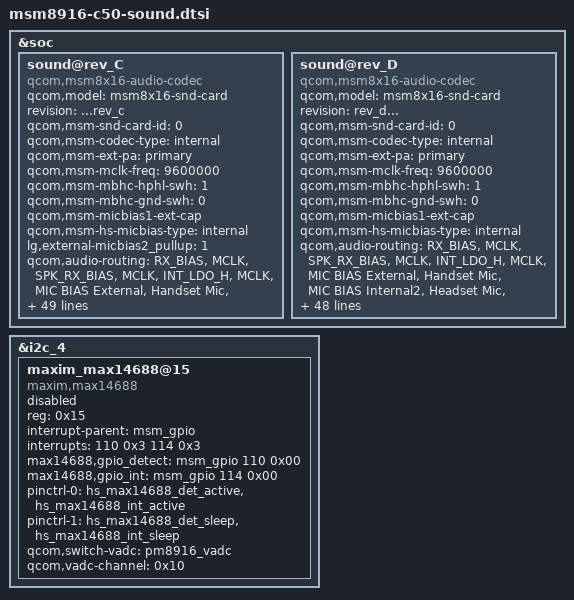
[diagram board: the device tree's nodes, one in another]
/* Copyright (c) 2012, Code Aurora Forum. All rights reserved.
 *
 * This program is free software; you can redistribute it and/or modify
 * it under the terms of the GNU General Public License version 2 and
 * only version 2 as published by the Free Software Foundation.
 *
 * This program is distributed in the hope that it will be useful,
 * but WITHOUT ANY WARRANTY; without even the implied warranty of
 * MERCHANTABILITY or FITNESS FOR A PARTICULAR PURPOSE.  See the
 * GNU General Public License for more details.
 */

&soc {
	sound@rev_C {
		compatible = "qcom,msm8x16-audio-codec";
		qcom,model = "msm8x16-snd-card";
		revision = "...rev_c";
		qcom,msm-snd-card-id = <0>;
		qcom,msm-codec-type = "internal";
		qcom,msm-ext-pa = "primary";
		qcom,msm-mclk-freq = <9600000>;
		qcom,msm-mbhc-hphl-swh = <1>;	/*LGE AUDIO BSP MODIFIED 0 to 1*/
		qcom,msm-mbhc-gnd-swh = <0>;
		qcom,msm-micbias1-ext-cap;
		qcom,msm-hs-micbias-type = "internal";
		lg,external-micbias2_pullup = <1>;
		qcom,audio-routing =
			"RX_BIAS", "MCLK",
			"SPK_RX_BIAS", "MCLK",
			"INT_LDO_H", "MCLK",
			"MIC BIAS External", "Handset Mic",
			"MIC BIAS Internal2", "Headset Mic",
			"MIC BIAS External", "Secondary Mic",
			"AMIC1", "MIC BIAS External",
			"AMIC2", "MIC BIAS Internal2",
			"AMIC3", "MIC BIAS External",
			"DMIC1", "MIC BIAS Internal1",
			"MIC BIAS Internal1", "Digital Mic1",
			"DMIC2", "MIC BIAS Internal1",
			"MIC BIAS Internal1", "Digital Mic2";
		pinctrl-names = "cdc_lines_act",
				"cdc_lines_sus",
				"cdc_lines_sec_ext_act",
				"cdc_lines_sec_ext_sus",
				"cross_conn_det_act",
				"cross_conn_det_sus";
		pinctrl-0 = <&cdc_pdm_lines_act>;
		pinctrl-1 = <&cdc_pdm_lines_sus>;
		pinctrl-2 = <&cdc_pdm_lines_act &cdc_ext_pa_act
						&cdc_ext_pa_ws_act>;
		pinctrl-3 = <&cdc_pdm_lines_sus &cdc_ext_pa_sus
						&cdc_ext_pa_ws_sus>;
		pinctrl-4 = <&cross_conn_det_act>;
		pinctrl-5 = <&cross_conn_det_sus>;
		//qcom,cdc-us-euro-gpios = <&msm_gpio 120 0>; /*LGE AUDIO BSP MODIFIED do not use*/
		asoc-platform = <&pcm0>, <&pcm1>, <&voip>, <&voice>,
				<&loopback>, <&compress>, <&hostless>,
				<&afe>, <&lsm>, <&routing>, <&lpa>;
		asoc-platform-names = "msm-pcm-dsp.0", "msm-pcm-dsp.1",
				"msm-voip-dsp", "msm-pcm-voice", "msm-pcm-loopback",
				"msm-compress-dsp", "msm-pcm-hostless", "msm-pcm-afe",
				"msm-lsm-client", "msm-pcm-routing", "msm-pcm-lpa";
		asoc-cpu = <&dai_pri_auxpcm>, <&dai_hdmi>,
				<&dai_mi2s0>, <&dai_mi2s1>, <&dai_mi2s2>, <&dai_mi2s3>,
				<&sb_0_rx>, <&sb_0_tx>, <&sb_1_rx>, <&sb_1_tx>,
				<&sb_3_rx>, <&sb_3_tx>, <&sb_4_rx>, <&sb_4_tx>,
				<&bt_sco_rx>, <&bt_sco_tx>, <&int_fm_rx>, <&int_fm_tx>,
				<&afe_pcm_rx>, <&afe_pcm_tx>, <&afe_proxy_rx>, <&afe_proxy_tx>,
				<&incall_record_rx>, <&incall_record_tx>, <&incall_music_rx>,
				<&incall_music_2_rx>;
		asoc-cpu-names = "msm-dai-q6-auxpcm.1", "msm-dai-q6-hdmi.8",
				"msm-dai-q6-mi2s.0", "msm-dai-q6-mi2s.1",
				"msm-dai-q6-mi2s.2", "msm-dai-q6-mi2s.3",
				"msm-dai-q6-dev.16384", "msm-dai-q6-dev.16385",
				"msm-dai-q6-dev.16386", "msm-dai-q6-dev.16387",
				"msm-dai-q6-dev.16390", "msm-dai-q6-dev.16391",
				"msm-dai-q6-dev.16392", "msm-dai-q6-dev.16393",
				"msm-dai-q6-dev.12288", "msm-dai-q6-dev.12289",
				"msm-dai-q6-dev.12292", "msm-dai-q6-dev.12293",
				"msm-dai-q6-dev.224", "msm-dai-q6-dev.225",
				"msm-dai-q6-dev.241", "msm-dai-q6-dev.240",
				"msm-dai-q6-dev.32771", "msm-dai-q6-dev.32772",
				"msm-dai-q6-dev.32773", "msm-dai-q6-dev.32770";
		asoc-codec = <&stub_codec>, <&pm8916_tombak_dig>;
		asoc-codec-names = "msm-stub-codec.1", "tombak_codec";
	};
	sound@rev_D {
		compatible = "qcom,msm8x16-audio-codec";
		qcom,model = "msm8x16-snd-card";
		revision = "rev_d...";
		qcom,msm-snd-card-id = <0>;
		qcom,msm-codec-type = "internal";
		qcom,msm-ext-pa = "primary";
		qcom,msm-mclk-freq = <9600000>;
		qcom,msm-mbhc-hphl-swh = <1>;	/*LGE AUDIO BSP MODIFIED 0 to 1*/
		qcom,msm-mbhc-gnd-swh = <0>;
		qcom,msm-micbias1-ext-cap;
		qcom,msm-hs-micbias-type = "internal";
		qcom,audio-routing =
			"RX_BIAS", "MCLK",
			"SPK_RX_BIAS", "MCLK",
			"INT_LDO_H", "MCLK",
			"MIC BIAS External", "Handset Mic",
			"MIC BIAS Internal2", "Headset Mic",
			"MIC BIAS External", "Secondary Mic",
			"AMIC1", "MIC BIAS External",
			"AMIC2", "MIC BIAS Internal2",
			"AMIC3", "MIC BIAS External",
			"DMIC1", "MIC BIAS Internal1",
			"MIC BIAS Internal1", "Digital Mic1",
			"DMIC2", "MIC BIAS Internal1",
			"MIC BIAS Internal1", "Digital Mic2";
		pinctrl-names = "cdc_lines_act",
				"cdc_lines_sus",
				"cdc_lines_sec_ext_act",
				"cdc_lines_sec_ext_sus",
				"cross_conn_det_act",
				"cross_conn_det_sus";
		pinctrl-0 = <&cdc_pdm_lines_act>;
		pinctrl-1 = <&cdc_pdm_lines_sus>;
		pinctrl-2 = <&cdc_pdm_lines_act &cdc_ext_pa_act
						&cdc_ext_pa_ws_act>;
		pinctrl-3 = <&cdc_pdm_lines_sus &cdc_ext_pa_sus
						&cdc_ext_pa_ws_sus>;
		pinctrl-4 = <&cross_conn_det_act>;
		pinctrl-5 = <&cross_conn_det_sus>;
		//qcom,cdc-us-euro-gpios = <&msm_gpio 120 0>; /*LGE AUDIO BSP MODIFIED do not use*/
		asoc-platform = <&pcm0>, <&pcm1>, <&voip>, <&voice>,
				<&loopback>, <&compress>, <&hostless>,
				<&afe>, <&lsm>, <&routing>, <&lpa>;
		asoc-platform-names = "msm-pcm-dsp.0", "msm-pcm-dsp.1",
				"msm-voip-dsp", "msm-pcm-voice", "msm-pcm-loopback",
				"msm-compress-dsp", "msm-pcm-hostless", "msm-pcm-afe",
				"msm-lsm-client", "msm-pcm-routing", "msm-pcm-lpa";
		asoc-cpu = <&dai_pri_auxpcm>, <&dai_hdmi>,
				<&dai_mi2s0>, <&dai_mi2s1>, <&dai_mi2s2>, <&dai_mi2s3>,
				<&sb_0_rx>, <&sb_0_tx>, <&sb_1_rx>, <&sb_1_tx>,
				<&sb_3_rx>, <&sb_3_tx>, <&sb_4_rx>, <&sb_4_tx>,
				<&bt_sco_rx>, <&bt_sco_tx>, <&int_fm_rx>, <&int_fm_tx>,
				<&afe_pcm_rx>, <&afe_pcm_tx>, <&afe_proxy_rx>, <&afe_proxy_tx>,
				<&incall_record_rx>, <&incall_record_tx>, <&incall_music_rx>,
				<&incall_music_2_rx>;
		asoc-cpu-names = "msm-dai-q6-auxpcm.1", "msm-dai-q6-hdmi.8",
				"msm-dai-q6-mi2s.0", "msm-dai-q6-mi2s.1",
				"msm-dai-q6-mi2s.2", "msm-dai-q6-mi2s.3",
				"msm-dai-q6-dev.16384", "msm-dai-q6-dev.16385",
				"msm-dai-q6-dev.16386", "msm-dai-q6-dev.16387",
				"msm-dai-q6-dev.16390", "msm-dai-q6-dev.16391",
				"msm-dai-q6-dev.16392", "msm-dai-q6-dev.16393",
				"msm-dai-q6-dev.12288", "msm-dai-q6-dev.12289",
				"msm-dai-q6-dev.12292", "msm-dai-q6-dev.12293",
				"msm-dai-q6-dev.224", "msm-dai-q6-dev.225",
				"msm-dai-q6-dev.241", "msm-dai-q6-dev.240",
				"msm-dai-q6-dev.32771", "msm-dai-q6-dev.32772",
				"msm-dai-q6-dev.32773", "msm-dai-q6-dev.32770";
		asoc-codec = <&stub_codec>, <&pm8916_tombak_dig>;
		asoc-codec-names = "msm-stub-codec.1", "tombak_codec";
	};
};

&i2c_4 {
	maxim_max14688@15 {
		compatible = "maxim,max14688";
		status = "disabled";
		reg = <0x15>;
		interrupt-parent = <&msm_gpio>;
		interrupts = <110 0x3 114 0x3>;
		max14688,gpio_detect = <&msm_gpio 110 0x00>; /* EAR_SENSE */
		max14688,gpio_int = <&msm_gpio 114 0x00>; /* EAR_KEY - insertion/removal IRQ */
		pinctrl-names = "default", "sleep";
		pinctrl-0 = <&hs_max14688_det_active &hs_max14688_int_active>;
		pinctrl-1 = <&hs_max14688_det_sleep &hs_max14688_int_sleep>;
		qcom,switch-vadc = <&pm8916_vadc>;
		qcom,vadc-channel = <0x10>; /* MPP 2 */
	};
};
